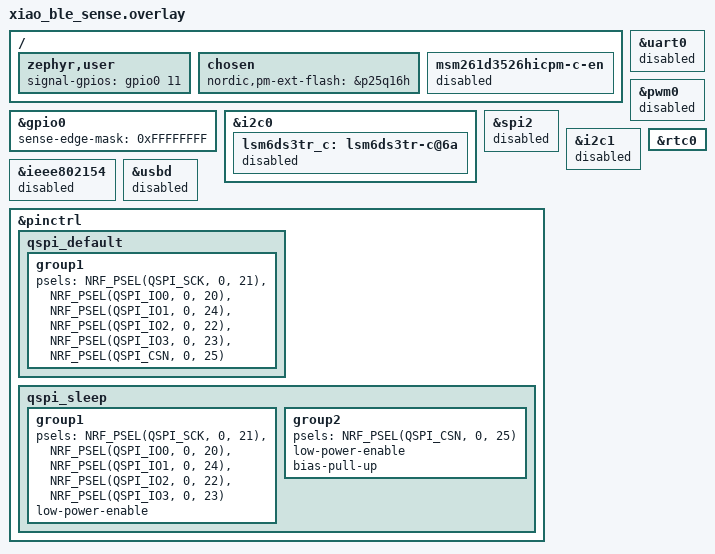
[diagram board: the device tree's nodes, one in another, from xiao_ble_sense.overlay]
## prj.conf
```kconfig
CONFIG_ASSERT=y
#memory
CONFIG_FLASH=y
CONFIG_FLASH_PAGE_LAYOUT=y
CONFIG_FLASH_MAP=y
CONFIG_NVS=y
CONFIG_NORDIC_QSPI_NOR=y
CONFIG_NORDIC_QSPI_NOR_FLASH_LAYOUT_PAGE_SIZE=4096
CONFIG_HEAP_MEM_POOL_SIZE=2048
CONFIG_NANOPB=y

#battery
CONFIG_ADC=y
CONFIG_ADC_NRFX_SAADC=y

CONFIG_I2C=y
CONFIG_SPI=n
CONFIG_CLOCK_CONTROL_NRF_K32SRC_XTAL=y
CONFIG_POSIX_CLOCK=y
CONFIG_BOARD_ENABLE_DCDC=y

#bluetooth
CONFIG_BT=y
CONFIG_SETTINGS=y
CONFIG_BT_SMP=y
CONFIG_BT_SIGNING=y
CONFIG_BT_PERIPHERAL=y
CONFIG_BT_ATT_PREPARE_COUNT=5
CONFIG_BT_BAS=y
#CONFIG_BT_DIS=y


CONFIG_BT_PRIVACY=y
CONFIG_BT_DEVICE_NAME="UU_tracker"
CONFIG_BT_DEVICE_APPEARANCE=541
CONFIG_BT_DEVICE_NAME_DYNAMIC=n
#CONFIG_BT_DEVICE_NAME_MAX=65
CONFIG_BT_SETTINGS=y
CONFIG_BT_USER_DATA_LEN_UPDATE=y


CONFIG_BT_BUF_ACL_RX_SIZE=83
CONFIG_BT_L2CAP_TX_MTU=83
CONFIG_BT_L2CAP_DYNAMIC_CHANNEL=y
CONFIG_BT_BUF_ACL_TX_COUNT=10
CONFIG_BT_BUF_ACL_TX_SIZE=83


CONFIG_BT_CTLR_DATA_LENGTH_MAX=83
CONFIG_BT_CTLR_PHY_2M=n
CONFIG_BT_CTLR_PHY_CODED=y

CONFIG_GPIO=y

#power savings
CONFIG_PM_DEVICE=y
CONFIG_USB_DEVICE_STACK=n
CONFIG_POWEROFF=y

CONFIG_LOG=n

#no-uf2
CONFIG_BUILD_OUTPUT_UF2=n
CONFIG_USE_DT_CODE_PARTITION=n
```

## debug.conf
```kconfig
#debug section
#xia debug
CONFIG_BUILD_OUTPUT_UF2=n
CONFIG_USE_DT_CODE_PARTITION=n

CONFIG_CORTEX_M_DEBUG_MONITOR_HOOK=y
CONFIG_SEGGER_DEBUGMON=y
CONFIG_DEBUG_OPTIMIZATIONS=y
CONFIG_DEBUG_THREAD_INFO=y
CONFIG_LOG=y 
CONFIG_BT_DEVICE_NAME="UU_tracker_DEBUG"

CONFIG_RTT_CONSOLE=y
CONFIG_USE_SEGGER_RTT=y

CONFIG_CBPRINTF_FP_SUPPORT=y
```

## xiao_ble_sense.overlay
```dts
/ {
    zephyr,user {
        signal-gpios = <&gpio0 11 GPIO_ACTIVE_HIGH>;
        
    };

    chosen {
        nordic,pm-ext-flash = &p25q16h;
    };

	msm261d3526hicpm-c-en {
		status = "disabled";
	};
};

&gpio0 {
    sense-edge-mask = <0xFFFFFFFF>; //<0x400>;
};


&i2c0 {	
    lsm6ds3tr_c: lsm6ds3tr-c@6a {
        status = "disabled";
    };
};

&uart0 {
    status = "disabled";
};

&pwm0 {
    status = "disabled"; 
};

&spi2 {
    status = "disabled";
};

&i2c1 {
    status = "disabled";
};

&ieee802154 {
    status = "disabled";
};

&rtc0 {
	status = "okay";
};

&usbd {
    status = "disabled";
};

&pinctrl {
    qspi_default: qspi_default {
		group1 {
			psels = <NRF_PSEL(QSPI_SCK, 0, 21)>,
				<NRF_PSEL(QSPI_IO0, 0, 20)>,
				<NRF_PSEL(QSPI_IO1, 0, 24)>,
				<NRF_PSEL(QSPI_IO2, 0, 22)>,
				<NRF_PSEL(QSPI_IO3, 0, 23)>,
				<NRF_PSEL(QSPI_CSN, 0, 25)>;
		};
	};

	qspi_sleep: qspi_sleep {
		group1 {
			psels = <NRF_PSEL(QSPI_SCK, 0, 21)>,
				<NRF_PSEL(QSPI_IO0, 0, 20)>,
				<NRF_PSEL(QSPI_IO1, 0, 24)>,
				<NRF_PSEL(QSPI_IO2, 0, 22)>,
				<NRF_PSEL(QSPI_IO3, 0, 23)>;
			low-power-enable;
		};
        group2 {
			psels = <NRF_PSEL(QSPI_CSN, 0, 25)>;
			low-power-enable;
			bias-pull-up;
		};
	};
};
```

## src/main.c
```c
#include <zephyr/kernel.h>
#include <zephyr/device.h>

#include <zephyr/devicetree.h>
#include <zephyr/drivers/gpio.h>

#include <stdio.h>
#include <zephyr/sys/util.h>
#include "storage_nvs.h"
#include "lsm6dsl_load.h"
#include "ble_load.h"
#include "battery.h"
#include <zephyr/logging/log.h>
#include <zephyr/sys/poweroff.h>

K_HEAP_DEFINE(BUFFER,512);

LOG_MODULE_REGISTER(MAIN, CONFIG_LOG_DEFAULT_LEVEL);

int main(void)
{		
	k_sleep(K_FOREVER);							
}
```

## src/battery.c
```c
/*
 * Copyright 2024 Marcus Alexander Tjomsaas
 *
 * Licensed under the Apache License, Version 2.0 (the "License");
 * you may not use this file except in compliance with the License.
 * You may obtain a copy of the License at
 *
 *     http://www.apache.org/licenses/LICENSE-2.0
 *
 * Unless required by applicable law or agreed to in writing, software
 * distributed under the License is distributed on an "AS IS" BASIS,
 * WITHOUT WARRANTIES OR CONDITIONS OF ANY KIND, either express or implied.
 * See the License for the specific language governing permissions and
 * limitations under the License.
 */

#include "battery.h"
#include <zephyr/bluetooth/services/bas.h>
#include <zephyr/kernel.h>
#include <zephyr/device.h>
#include <zephyr/devicetree.h>
#include <zephyr/drivers/gpio.h>
#include <zephyr/drivers/adc.h>
#include <zephyr/logging/log.h>

LOG_MODULE_REGISTER(battery, LOG_LEVEL_INF);

static void update_ble_handler(struct k_work *work);

K_WORK_DELAYABLE_DEFINE(ble_send_work, update_ble_handler);


static int16_t sample_buffer[ADC_TOTAL_SAMPLES];

static struct adc_sequence_options options = {
    .extra_samplings = ADC_TOTAL_SAMPLES - 1,
    .interval_us = ADC_SAMPLE_INTERVAL_US,
};

static struct adc_sequence sequence = {
    .options = &options,
    .channels = BIT(ADC_CHANNEL),
    .buffer = sample_buffer,
    .buffer_size = sizeof(sample_buffer),
    .resolution = ADC_RESOLUTION,
};

static struct adc_channel_cfg channel_7_cfg = {
    .gain = ADC_GAIN,
    .reference = ADC_REFERENCE,
    .acquisition_time = ADC_ACQ_TIME_DEFAULT,
    .channel_id = ADC_CHANNEL,
#ifdef CONFIG_ADC_NRFX_SAADC
    .input_positive = ADC_PORT
#endif
};

// MCU peripherals for reading battery voltage
static const struct device *gpio_battery_dev = DEVICE_DT_GET(DT_NODELABEL(gpio0));
static const struct device *adc_battery_dev = DEVICE_DT_GET(DT_NODELABEL(adc));

// Charging interrupt

static K_MUTEX_DEFINE(battery_mut);

// Assuming LiPo battery.
// For better accuracy, use your battery's datasheet.
static BatteryState battery_states[BATTERY_STATES_COUNT] = {
    {4200, 100},
    {4160, 99},
    {4090, 91},
    {4030, 78},
    {3890, 63},
    {3830, 53},
    {3680, 36},
    {3660, 35},
    {3480, 14},
    {3420, 11},
    {3150, 1}, // 3240
    {0000, 0}  // Below safe level
};

int battery_get_millivolt(uint16_t *battery_millivolt)
{

    int ret = 0;

    // Voltage divider circuit (Should tune R1 in software if possible)
    const uint16_t R1 = 1037; // Originally 1M ohm, calibrated after measuring actual voltage values. Can happen due to resistor tolerances, temperature ect..
    const uint16_t R2 = 510;  // 510K ohm
    
    int adc_mv = 0;
    
    ret |= k_mutex_lock(&battery_mut, K_FOREVER);
    ret |= gpio_pin_set(gpio_battery_dev, GPIO_BATTERY_READ_ENABLE, 1);
    ret |= adc_read(adc_battery_dev, &sequence);
    uint16_t adc_vref = adc_ref_internal(adc_battery_dev);

    // Get average sample value.
    for (uint8_t sample = 0; sample < ADC_TOTAL_SAMPLES; sample++)
    {
        adc_mv += sample_buffer[sample]; // ADC value, not millivolt yet.
    }
    adc_mv /= ADC_TOTAL_SAMPLES;

    // Convert ADC value to millivolts
    ret |= adc_raw_to_millivolts(adc_vref, ADC_GAIN, ADC_RESOLUTION, &adc_mv);

    // Calculate battery voltage.
    *battery_millivolt = adc_mv * ((R1 + R2) / R2);

    ret |= gpio_pin_set(gpio_battery_dev, GPIO_BATTERY_READ_ENABLE, 0);

    k_mutex_unlock(&battery_mut);

    LOG_DBG("%d mV", *battery_millivolt);
    return ret;
}

int battery_get_percentage(uint8_t *battery_percentage, uint16_t battery_millivolt)
{

    // Ensure voltage is within bounds
    if (battery_millivolt > battery_states[0].voltage)
        *battery_percentage = 100;
    if (battery_millivolt < battery_states[BATTERY_STATES_COUNT - 1].voltage)
        *battery_percentage = 0;

    for (uint16_t i = 0; i < BATTERY_STATES_COUNT - 1; i++)
    {
        // Find the two points battery_millivolt is between
        if (battery_states[i].voltage >= battery_millivolt && battery_millivolt >= battery_states[i + 1].voltage)
        {
            // Linear interpolation
            *battery_percentage = battery_states[i].percentage +
                                  ((float)(battery_millivolt - battery_states[i].voltage) *
                                   ((float)(battery_states[i + 1].percentage - battery_states[i].percentage) /
                                    (float)(battery_states[i + 1].voltage - battery_states[i].voltage)));

            LOG_DBG("%d %%", *battery_percentage);
            return 0;
        }
    }
    return -ESPIPE;
}


static void update_ble_handler(struct k_work *work) {
    
    uint8_t percentage = 0;
    uint16_t millivolt = 0;
    battery_get_millivolt(&millivolt);

    battery_get_percentage(&percentage, millivolt);
    bt_bas_set_battery_level(percentage);
    LOG_INF("update_ble mV %d, percentage %d", millivolt, percentage);
    k_work_schedule(&ble_send_work, K_MINUTES(BAS_UPDATE_FREQUENCY));
}

int battery_init()
{
    int ret = 0;

    ret |= adc_channel_setup(adc_battery_dev, &channel_7_cfg);        
    ret |= gpio_pin_configure(gpio_battery_dev, GPIO_BATTERY_READ_ENABLE, GPIO_OUTPUT | GPIO_ACTIVE_LOW);
    ret |= gpio_pin_configure(gpio_battery_dev, GPIO_BATTERY_CHARGE_SPEED, GPIO_OUTPUT | GPIO_ACTIVE_LOW);
    ret |= gpio_pin_set(gpio_battery_dev, GPIO_BATTERY_CHARGE_SPEED, 1); // FAST charge 100mA
    
    LOG_INF("Initialized");
    
    k_work_schedule(&ble_send_work, K_MINUTES(BAS_UPDATE_FREQUENCY));

    return ret;
}

SYS_INIT(battery_init, APPLICATION, CONFIG_APPLICATION_INIT_PRIORITY);
```

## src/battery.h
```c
/*
 * Copyright 2024 Marcus Alexander Tjomsaas
 *
 * Licensed under the Apache License, Version 2.0 (the "License");
 * you may not use this file except in compliance with the License.
 * You may obtain a copy of the License at
 *
 *     http://www.apache.org/licenses/LICENSE-2.0
 *
 * Unless required by applicable law or agreed to in writing, software
 * distributed under the License is distributed on an "AS IS" BASIS,
 * WITHOUT WARRANTIES OR CONDITIONS OF ANY KIND, either express or implied.
 * See the License for the specific language governing permissions and
 * limitations under the License.
 */

#include <stdint.h>
#include <stdbool.h>

#ifndef __BATTERY_H__
#define __BATTERY_H__

#define BAS_UPDATE_FREQUENCY 2
#define GPIO_BATTERY_CHARGE_SPEED 13
#define GPIO_BATTERY_CHARGING_ENABLE 17
#define GPIO_BATTERY_READ_ENABLE 14

// Change this to a higher number for better averages
// Note that increasing this holds up the thread / ADC for longer.
#define ADC_TOTAL_SAMPLES 10

//--------------------------------------------------------------
// ADC setup

#define ADC_RESOLUTION 12
#define ADC_CHANNEL 7
#define ADC_PORT SAADC_CH_PSELP_PSELP_AnalogInput7 // AIN7
#define ADC_REFERENCE ADC_REF_INTERNAL             // 0.6V
#define ADC_GAIN ADC_GAIN_1_6                      // ADC REFERENCE * 6 = 3.6V
#define ADC_SAMPLE_INTERVAL_US 500                 // Time between each sample
#define BATTERY_STATES_COUNT 12


typedef struct
{
    uint16_t voltage;
    uint8_t percentage;
} BatteryState;


/**
 * @brief Calculates the battery voltage using the ADC.
 *
 * @param[in] battery_millivolt Pointer to where battery voltage is stored.
 *
 * @retval 0 if successful. Negative errno number on error.
 */
int battery_get_millivolt(uint16_t *battery_millivolt);

/**
 * @brief Calculates the battery percentage using the battery voltage.
 *
 * @param[in] battery_percentage  Pointer to where battery percentage is stored.
 *
 * @param[in] battery_millivolt Voltage used to calculate the percentage of how much energy is left in a 3.7V LiPo battery.
 *
 * @retval 0 if successful. Negative errno number on error.
 */
int battery_get_percentage(uint8_t *battery_percentage, uint16_t battery_millivolt);


#endif
```

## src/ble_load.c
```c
#include <zephyr/types.h>
#include <stddef.h>
#include <string.h>
#include <errno.h>

#include <zephyr/sys/byteorder.h>
#include <zephyr/kernel.h>

#include <zephyr/settings/settings.h>

#include <zephyr/bluetooth/bluetooth.h>
#include <zephyr/bluetooth/hci.h>
#include <zephyr/bluetooth/conn.h>
#include <zephyr/bluetooth/uuid.h>
#include <zephyr/bluetooth/gatt.h>

#include <zephyr/logging/log.h>
#include <pb_encode.h>
#include <pb_decode.h>
#include "motion.pb.h"
#include "storage_nvs.h"


#define protobuf_chunk_size 64 //*13 = 247, actual 246 byte protobuf total/max mTU= 20byte
#define protobuf_buffer_size ROUND_UP(HourlyResult_size, protobuf_chunk_size)
//#define ble_chunks_to_send ROUND_UP(HourlyResult_size/protobuf_chunk_size, 1) //more than enough

LOG_MODULE_REGISTER(bluetooth_m, CONFIG_LOG_DEFAULT_LEVEL);

void ble_notify_motiondata_proc(struct k_work *ptrWorker);
void ble_send_passcode(struct k_work *work);

K_WORK_DEFINE(ble_passcode_worker, ble_send_passcode);
K_WORK_DEFINE(work_get_acc_data, ble_notify_motiondata_proc);

//custom service
static struct bt_uuid_128 motiondata_prop = BT_UUID_INIT_128(
	BT_UUID_128_ENCODE(0xa6c47c93, 0x8a09, 0x4ca5, 0x976e, 0xde7b871f11f0));

//ble key
static struct bt_uuid_128 ble_pw_prop = BT_UUID_INIT_128(
	BT_UUID_128_ENCODE(0xd97b1503, 0xa25c, 0x4295, 0xbd21, 0xf96823d91552));

//unique device
static struct bt_uuid_128 ble_device_identifier_prop = BT_UUID_INIT_128(
	BT_UUID_128_ENCODE(0x56a332cc, 0x0379, 0x497e, 0xbd2d, 0xe778c69badd6));

//current memory position
static struct bt_uuid_128 ble_memory_position_prop = BT_UUID_INIT_128(
	BT_UUID_128_ENCODE(0x84b45135, 0x170b, 0x4d03, 0x92b6, 0x386d7bff160d));

//accelometer data server (protobuf)
static struct bt_uuid_128 ble_accelometer_data_prop = BT_UUID_INIT_128(
	BT_UUID_128_ENCODE(0x6f2648ed, 0xe73f, 0x4b9f, 0xa809, 0xb1686d18676c));

//accelometer requist data
static struct bt_uuid_128 ble_accelometer_requist_id_prop = BT_UUID_INIT_128(
	BT_UUID_128_ENCODE(0x4e10fd71, 0x6cc1, 0x4fa7, 0xaa91, 0x82021582ca54));



static uint8_t ble_accelometer_data_buff[protobuf_chunk_size]; //size of packed protobuf
static uint8_t ble_requist_id_buff[2]; //uint16 flash location

//write flash ID to respond to
static ssize_t write_acc_data_position(struct bt_conn *conn, const struct bt_gatt_attr *attr,
 			 const void *buf, uint16_t len, uint16_t offset,
 			 uint8_t flags) {

 	uint8_t *value = attr->user_data;

	if (offset + len > sizeof(ble_requist_id_buff)) {
		return BT_GATT_ERR(BT_ATT_ERR_INVALID_OFFSET);
	}
	memcpy(value + offset, buf, len);	
	
	k_work_submit(&work_get_acc_data);
	
 	return len;
}
//read flash ID that has been responded to
static ssize_t read_acc_data_position(struct bt_conn *conn, const struct bt_gatt_attr *attr,
			void *buf, uint16_t len, uint16_t offset)
{
	const uint8_t *value = attr->user_data;	

	return bt_gatt_attr_read(conn, attr, buf, len, offset, value, sizeof(ble_requist_id_buff));
}

//read last chunk of protobuffed data 
static ssize_t read_acc_data(struct bt_conn *conn, const struct bt_gatt_attr *attr,
			void *buf, uint16_t len, uint16_t offset)
{	
	
	const uint8_t *value = attr->user_data;	

	return bt_gatt_attr_read(conn, attr, buf, len, offset, value, sizeof(ble_accelometer_data_buff));
}

//protobuf encode sensor data 
//todo: might want to use double?
static int encode_data(struct fifo_pack *stored_data, uint8_t *protobuf_packed, size_t *packed_size) {
	bool status;

	HourlyResult message = HourlyResult_init_zero;	
	/* Create a stream that will write to our buffer. */
	pb_ostream_t stream = pb_ostream_from_buffer(protobuf_packed, HourlyResult_size);
	
	message.UnixTime = stored_data->seconds_passed;

	BUILD_ASSERT(ARRAY_SIZE(message.AvgMinuteList) == FLASH_BUFFER_SIZE_NVS, "Error buffer not equal to array size");
	for(int i = 0; i<FLASH_BUFFER_SIZE_NVS; i++) {
		message.AvgMinuteList[i] = stored_data->vector_n[i];
	}	

	status = pb_encode(&stream, &HourlyResult_msg, &message);
	*packed_size = stream.bytes_written;

	LOG_INF("Encoded, actual protobuf message size was %d", stream.bytes_written); //PRIu64

	if (!status) {
		LOG_ERR("Encoding failed: %s\n", PB_GET_ERROR(&stream));
	}

	return status;
}


static uint8_t current_memoryPosition_buff[2];
static ssize_t read_memory_position(struct bt_conn *conn, const struct bt_gatt_attr *attr,
			void *buf, uint16_t len, uint16_t offset)
{
	uint16_t mem_pos = 0;
	get_current_storage_id(&mem_pos);
	memcpy(current_memoryPosition_buff, &mem_pos, sizeof(uint16_t));

	const uint8_t *value = attr->user_data;	

	return bt_gatt_attr_read(conn, attr, buf, len, offset, value, sizeof(current_memoryPosition_buff));
}

static ssize_t write_memory_position(struct bt_conn *conn, const struct bt_gatt_attr *attr,
 			 const void *buf, uint16_t len, uint16_t offset,
 			 uint8_t flags) {

 	uint8_t *value = attr->user_data;

	if (offset + len > sizeof(current_memoryPosition_buff)) {
		return BT_GATT_ERR(BT_ATT_ERR_INVALID_OFFSET);
	}
	memcpy(value + offset, buf, len);

	uint16_t memory_position = 0;
	memcpy(&memory_position, current_memoryPosition_buff, sizeof(uint16_t));
	set_current_storage_id(&memory_position);
	//memcpy(&memory_position, value, sizeof(uint16_t));	
	
 	return len;
}


static uint8_t ble_passcode_buff[4];
static ssize_t read_passcode(struct bt_conn *conn, const struct bt_gatt_attr *attr,
			void *buf, uint16_t len, uint16_t offset)
{
	const uint8_t *value = attr->user_data;	

	return bt_gatt_attr_read(conn, attr, buf, len, offset, value, sizeof(ble_passcode_buff));
}

static uint8_t uniqueIdentifier_value[sizeof(uint16_t)];

static ssize_t read_identifier(struct bt_conn *conn, const struct bt_gatt_attr *attr,
			void *buf, uint16_t len, uint16_t offset) {

	uint16_t uniqueId = 0;
	read_uniqueidentifier(&uniqueId);
	memcpy(uniqueIdentifier_value, &uniqueId, sizeof(uint16_t));

	const uint8_t *value = attr->user_data;	

	return bt_gatt_attr_read(conn, attr, buf, len, offset, value, sizeof(uniqueIdentifier_value));
}

static ssize_t write_identifier(struct bt_conn *conn, const struct bt_gatt_attr *attr,
 			 const void *buf, uint16_t len, uint16_t offset,
 			 uint8_t flags) {

 	uint8_t *value = attr->user_data;

	if (offset + len > sizeof(uniqueIdentifier_value)) {
		return BT_GATT_ERR(BT_ATT_ERR_INVALID_OFFSET);
	}
	memcpy(value + offset, buf, len);

	uint16_t uniqueId = 0;
	memcpy(&uniqueId, value, sizeof(uint16_t));
	write_uniqueIdentifier(&uniqueId);
	
 	return len;
}

static uint8_t notify_ble_passcode_on = 0;
static uint8_t notify_ble_motiondata_on = 0;

static void ble_readmotion_data_notify_changed(const struct bt_gatt_attr *attr, uint16_t value) {
	notify_ble_motiondata_on = (value == BT_GATT_CCC_NOTIFY) ? 1 : 0;
}

static void ble_passcode_notify_changed(const struct bt_gatt_attr *attr, uint16_t value) {
	notify_ble_passcode_on = (value == BT_GATT_CCC_NOTIFY) ? 1 : 0;
}

/* Motion readout primary Service Declaration */
BT_GATT_SERVICE_DEFINE(motion_svc,
	BT_GATT_PRIMARY_SERVICE(&motiondata_prop),
	BT_GATT_CHARACTERISTIC(&ble_pw_prop.uuid,
			       BT_GATT_CHRC_READ | BT_GATT_CHRC_NOTIFY,
			       BT_GATT_PERM_READ,
			       read_passcode, NULL, ble_passcode_buff),	
	BT_GATT_CCC(ble_passcode_notify_changed,   BT_GATT_PERM_READ | BT_GATT_PERM_WRITE),
	
	BT_GATT_CHARACTERISTIC(&ble_device_identifier_prop.uuid,
			       BT_GATT_CHRC_READ | BT_GATT_CHRC_WRITE,
			       BT_GATT_PERM_READ | BT_GATT_PERM_WRITE,
			       read_identifier, write_identifier, uniqueIdentifier_value),

	BT_GATT_CHARACTERISTIC(&ble_memory_position_prop.uuid, 
	 		       BT_GATT_CHRC_READ | BT_GATT_CHRC_WRITE,
	 		       BT_GATT_PERM_READ | BT_GATT_PERM_WRITE,	 		       
	 		       read_memory_position, write_memory_position, current_memoryPosition_buff),

	BT_GATT_CHARACTERISTIC(&ble_accelometer_data_prop.uuid, 
	 		       BT_GATT_CHRC_READ | BT_GATT_CHRC_NOTIFY,
	 		       BT_GATT_PERM_READ,
	 		       read_acc_data, NULL, ble_accelometer_data_buff),
	BT_GATT_CCC(ble_readmotion_data_notify_changed, BT_GATT_PERM_READ | BT_GATT_PERM_WRITE),
	
	BT_GATT_CHARACTERISTIC(&ble_accelometer_requist_id_prop.uuid, 
	 		       BT_GATT_CHRC_READ | BT_GATT_CHRC_WRITE,
	 		       BT_GATT_PERM_READ | BT_GATT_PERM_WRITE,
	 		       read_acc_data_position, write_acc_data_position, ble_requist_id_buff),

);

void ble_send_passcode(struct k_work *work) {				
	
	if(notify_ble_passcode_on)
		bt_gatt_notify(NULL, &motion_svc.attrs[1], ble_passcode_buff, sizeof(ble_passcode_buff));	
}

void print_data(uint8_t *data, uint32_t len) {
	char string[255] = {0};
    
    
    LOG_INF("%s\n", string);
}

K_SEM_DEFINE(sem_notify, 0, 1);

void notify_complete_cb(struct bt_conn *conn, void *user_data)
{
	int err = 0;
    if (err != 0) {
        LOG_ERR("Notification failed with error %d", err);
        return;
    }
	k_sem_give(&sem_notify);
}


/// @brief Notify BLE with all chunks of data 
/// @param ptrWorker 
void ble_notify_motiondata_proc(struct k_work *ptrWorker) {					

	if(!notify_ble_motiondata_on) return;
	struct fifo_pack packet;
	uint16_t id_to_retreive;
	memcpy(&id_to_retreive, ble_requist_id_buff, sizeof(uint16_t));
	LOG_INF("NOTIFY data, reteive id %d", id_to_retreive);				
	load_tracked(id_to_retreive, &packet);
	
	uint8_t encoded_data_cache[protobuf_buffer_size] = {0};
	size_t packed_size = 0;
	encode_data(&packet, encoded_data_cache+2, &packed_size); //shift data 2 bytes
	memcpy(encoded_data_cache, &packed_size, sizeof(uint16_t)); //first 2 bytes for size

	struct bt_gatt_attr *notify_attr = bt_gatt_find_by_uuid(motion_svc.attrs, motion_svc.attr_count, &ble_accelometer_data_prop.uuid);
	
    struct bt_gatt_notify_params params = {
        .attr = notify_attr,
        .data = ble_accelometer_data_buff,
        .len  = sizeof(ble_accelometer_data_buff),
        .func = notify_complete_cb, 
    };

	for(size_t offset = 0; offset < packed_size; offset+=protobuf_chunk_size) {
		memcpy(ble_accelometer_data_buff, encoded_data_cache + offset, protobuf_chunk_size);	
				
		LOG_INF("sending offset %d", offset);
		
		int ret = bt_gatt_notify_cb(NULL, &params);
		int semret = k_sem_take(&sem_notify, K_MSEC(200));
		if(ret<0) {
			LOG_ERR("error notify data %d", ret);	
		}			
		if(semret == -EAGAIN) {			
			LOG_ERR("semaphone timed out");
			return;
		}
	}	
}

const struct bt_data ad[] = {
		BT_DATA_BYTES(BT_DATA_FLAGS, (BT_LE_AD_GENERAL | BT_LE_AD_NO_BREDR)),
		BT_DATA_BYTES(BT_DATA_UUID16_ALL, BT_UUID_16_ENCODE(BT_UUID_BAS_VAL), BT_UUID_16_ENCODE(BT_UUID_CTS_VAL)),	};
		//BT_DATA_BYTES(BT_DATA_UUID128_ALL, motiondata_prop),
// 			BT_DATA(BT_DATA_MANUFACTURER_DATA, uniqueId, sizeof(ui))
// 	};
// }

void mtu_updated(struct bt_conn *conn, uint16_t tx, uint16_t rx)
{
	LOG_INF("Updated MTU: TX: %d RX: %d bytes\n", tx, rx);
}

static struct bt_gatt_cb gatt_callbacks = {
	.att_mtu_updated = mtu_updated
};

static void connected(struct bt_conn *conn, uint8_t err)
{
	if (err) {
		LOG_INF("Connection failed (err 0x%02x)\n", err);
	} else {
		LOG_INF("Connected\n");
	}
}

static void disconnected(struct bt_conn *conn, uint8_t reason)
{
	LOG_INF("Disconnected (reason 0x%02x)\n", reason);
}

static void le_data_length_updated(struct bt_conn *conn, struct bt_conn_le_data_len_info *info) {
	LOG_INF("LE data len updated: TX (len: %d time: %d)"
	       " RX (len: %d time: %d)\n", info->tx_max_len,
	       info->tx_max_time, info->rx_max_len, info->rx_max_time);
}

BT_CONN_CB_DEFINE(conn_callbacks) = {
	.connected = connected,
	.disconnected = disconnected,
	.le_data_len_updated = le_data_length_updated,
};



#define BT_CONN_CUSTOM BT_LE_ADV_PARAM(BT_LE_ADV_OPT_CONNECTABLE | \
					    BT_LE_ADV_OPT_USE_NAME, \
					    2048+512+64, 4098, NULL) //*1.25ms

static void bt_ready(void)
{
	int err;

	LOG_INF("Bluetooth initialized\n");	

	if (IS_ENABLED(CONFIG_SETTINGS)) {
		settings_load();
	}

	err = bt_le_adv_start(BT_CONN_CUSTOM, ad, ARRAY_SIZE(ad), NULL, 0);
	if (err) {
		LOG_ERR("Advertising failed to start (err %d)\n", err);
		return;
	}

	LOG_INF("Advertising successfully started\n");
}
/*
static void auth_passkey_display(struct bt_conn *conn, unsigned int passkey)
{
	char addr[BT_ADDR_LE_STR_LEN];
	bt_addr_le_to_str(bt_conn_get_dst(conn), addr, sizeof(addr));
	LOG_INF("Passkey for %s: %06u\n", addr, passkey);
	memcpy(ble_passcode_buff, (uint8_t*)&passkey, (sizeof(ble_passcode_buff)));	
	k_work_submit(&ble_passcode_worker);
	bt_conn_auth_passkey_confirm(conn);
}
*/
static void auth_cancel(struct bt_conn *conn)
{
	char addr[BT_ADDR_LE_STR_LEN];

	bt_addr_le_to_str(bt_conn_get_dst(conn), addr, sizeof(addr));

	LOG_INF("Pairing cancelled: %s\n", addr);
}

static struct bt_conn_auth_cb auth_cb_display = {
	.passkey_display = NULL,// auth_passkey_display,
	.passkey_entry = NULL,
	.cancel = auth_cancel,
	.passkey_confirm = NULL,	
};

int ble_load()
{		
	int err;

	err = bt_enable(NULL);
	if (err) {
		LOG_INF("Bluetooth init failed (err %d)\n", err);
		return 0;
	}

	bt_ready();

	bt_gatt_cb_register(&gatt_callbacks);
	bt_conn_auth_cb_register(&auth_cb_display);

	//clean up bonds
	bt_unpair(BT_ID_DEFAULT, BT_ADDR_LE_ANY);
	
	return err;
}

SYS_INIT(ble_load, APPLICATION, CONFIG_APPLICATION_INIT_PRIORITY);
```

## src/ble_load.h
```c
#ifndef BLE_LOAD_H
#define BLE_LOAD_H



#endif
```

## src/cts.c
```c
/** @file
 *  @brief CTS Service sample
 */

/*
 * Copyright (c) 2016 Intel Corporation
 *
 * SPDX-License-Identifier: Apache-2.0
 */

#include <zephyr/types.h>
#include <stddef.h>
#include <errno.h>
#include <zephyr/sys/byteorder.h>
#include <zephyr/kernel.h>

#include <zephyr/bluetooth/bluetooth.h>
#include <zephyr/bluetooth/hci.h>
#include <zephyr/bluetooth/conn.h>
#include <zephyr/bluetooth/uuid.h>
#include <zephyr/bluetooth/gatt.h>

#include <zephyr/posix/time.h>
#include <zephyr/sys/timeutil.h>
#include <zephyr/logging/log.h>
#include "cts.h"

//current time
static uint8_t ct[sizeof(time_t)];

LOG_MODULE_REGISTER(TIME_MODULE, CONFIG_LOG_DEFAULT_LEVEL);

void ble_update_time(struct k_work *work);

void timerElapsed(struct k_timer *timer_id);
K_WORK_DEFINE(notifyCTS, ble_update_time);

K_TIMER_DEFINE(update_time_timer, timerElapsed, NULL);

void timerElapsed(struct k_timer *timer_id) {
	k_work_submit(&notifyCTS);
}

void update_time_ble_buffer() {
	struct timespec ts = {
        .tv_sec = 0,
        .tv_nsec = 0,
    };

	clock_gettime(CLOCK_REALTIME, &ts);
	LOG_INF("update time, current: %" PRId64 ", size %d" , ts.tv_sec, sizeof(time_t));
	memcpy(&ct, &ts.tv_sec, sizeof(time_t));
}

static void ct_ccc_cfg_changed(const struct bt_gatt_attr *attr, uint16_t value)
{

	if(value) {
		k_timer_start(&update_time_timer, K_SECONDS(1), K_SECONDS(1));

	} else {
		k_timer_stop(&update_time_timer);
	}
}

static ssize_t read_ct(struct bt_conn *conn, const struct bt_gatt_attr *attr,
		       void *buf, uint16_t len, uint16_t offset)
{
	update_time_ble_buffer();
	const char *value = attr->user_data;	

	return bt_gatt_attr_read(conn, attr, buf, len, offset, value,
				 sizeof(ct));
}

int settime(time_t current_time) {
	int ret = 0;
	struct timespec ts = {0};
	ts.tv_sec = current_time;

    ret |= clock_settime(CLOCK_REALTIME, &ts);
	
	return ret;
}

static ssize_t write_ct(struct bt_conn *conn, const struct bt_gatt_attr *attr,
			const void *buf, uint16_t len, uint16_t offset,
			uint8_t flags)
{
	uint8_t *value = attr->user_data;

	if (offset + len > sizeof(ct)) {
		return BT_GATT_ERR(BT_ATT_ERR_INVALID_OFFSET);
	}

	memcpy(value + offset, buf, len);
		
	for(uint16_t i = 0; i<len; i++){
		LOG_INF("received %i", value[i]);
	}
	time_t timeconstruct = 0;
	memcpy(&timeconstruct, value, len);
	
	settime(timeconstruct);
	print_current_time();

	return len;
}

int print_current_time() {
	
    struct timespec ts = {0};      
	
	clock_gettime(CLOCK_REALTIME, &ts);
	struct tm *current_time = gmtime(&ts.tv_sec);

	LOG_INF("Current time: %04d-%02d-%02d %02d:%02d:%02d",
			current_time->tm_year + 1900, current_time->tm_mon + 1, current_time->tm_mday,
			current_time->tm_hour, current_time->tm_min, current_time->tm_sec);
	
	return 0;
}

/* Current Time Service Declaration */
BT_GATT_SERVICE_DEFINE(cts_cvs,
	BT_GATT_PRIMARY_SERVICE(BT_UUID_CTS),
	BT_GATT_CHARACTERISTIC(BT_UUID_CTS_CURRENT_TIME, BT_GATT_CHRC_READ |
			       BT_GATT_CHRC_NOTIFY | BT_GATT_CHRC_WRITE,
			       BT_GATT_PERM_READ | BT_GATT_PERM_WRITE,
			       read_ct, write_ct, ct),
	BT_GATT_CCC(ct_ccc_cfg_changed, BT_GATT_PERM_READ | BT_GATT_PERM_WRITE),
);

void ble_update_time(struct k_work *work)
{
    
	update_time_ble_buffer();
	// struct bt_gatt_attr *cts_not_attr;
	// cts_not_attr = bt_gatt_find_by_uuid(cts_cvs.attrs, cts_cvs.attr_count, BT_UUID_CTS_CURRENT_TIME);					
	
	bt_gatt_notify(NULL, &cts_cvs.attrs[1], ct, sizeof(ct));
	
}


//SYS_INIT(cts_init, APPLICATION, CONFIG_APPLICATION_INIT_PRIORITY);
```

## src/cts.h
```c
#ifndef CTS_LOAD_H
#define CTS_LOAD_H

int print_current_time();


#endif
```

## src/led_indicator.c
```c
#include <stdio.h>
#include <zephyr/kernel.h>
#include <zephyr/device.h>
#include <zephyr/drivers/gpio.h>


#define LED0_NODE DT_ALIAS(led0)
#define LED1_NODE DT_ALIAS(led1)
#define LED2_NODE DT_ALIAS(led2)
#define number_leds 3

static const struct gpio_dt_spec leds[] = {
    GPIO_DT_SPEC_GET(LED0_NODE, gpios),
    GPIO_DT_SPEC_GET(LED1_NODE, gpios),    
    GPIO_DT_SPEC_GET(LED2_NODE, gpios),    
};

static void switchof(struct k_work *work);

struct k_work_delayable dw_switchoffs [number_leds];

static int led_init() {
    int ret = 0;
    for(int x = 0; x< number_leds; x++) {
        ret |= gpio_pin_configure_dt(&leds[x], GPIO_OUTPUT_ACTIVE);
        ret |= gpio_pin_set_dt(&leds[x], 0);
        k_work_init_delayable(&dw_switchoffs[x], switchof);  
    }    
    
    return ret;
}

//K_WORK_DELAYABLE_DEFINE(dw_switchof, switchof);

static void switchof(struct k_work *work) {    
    struct k_work_delayable *dwork = k_work_delayable_from_work(work);
    int index = dwork - dw_switchoffs;    
    gpio_pin_set_dt(&leds[index], 0);    
}

void blink(uint8_t color) {    
    gpio_pin_set_dt(&leds[color], 1);
    k_work_schedule(&dw_switchoffs[color], K_MSEC(768));
}

SYS_INIT(led_init, APPLICATION, CONFIG_APPLICATION_INIT_PRIORITY);
```

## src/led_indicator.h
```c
#ifndef __led_indicator
#define __led_indicator



void blink(uint8_t color);

#endif
```

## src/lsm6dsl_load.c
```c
#include <zephyr/kernel.h>
#include <zephyr/device.h>
#include <zephyr/sys/util.h>
#include <zephyr/drivers/gpio.h>
#include <zephyr/drivers/i2c.h>
#include <zephyr/logging/log.h>
#include <math.h>
#include "storage_nvs.h"
#include "lsm6dsl_reg.h"
#include "lsm6dsl_load.h"
#include "led_indicator.h"

#include <zephyr/bluetooth/bluetooth.h>
#include <zephyr/bluetooth/hci.h>
#include <zephyr/bluetooth/conn.h>
#include <zephyr/bluetooth/uuid.h>
#include <zephyr/bluetooth/gatt.h>



BUILD_ASSERT(FIFO_BUFFER_LENGTH % fifo_pattern == 0, "FIFO_BUFFER_LENGTH should be devisible by fifo_pattern");

static const struct gpio_dt_spec signal = GPIO_DT_SPEC_GET(ZEPHYR_USER_NODE, signal_gpios);

LOG_MODULE_REGISTER(LSM6DSL_LOAD, CONFIG_LOG_DEFAULT_LEVEL);

static uint8_t whoamI, rst;
const struct device *i2c;
static struct gpio_callback lsm6dsl_interrupt;
static stmdev_ctx_t dev_ctx;

typedef union {
  int16_t i16bit[3];
  uint8_t u8bit[6];
} axis3bit16_t;

static axis3bit16_t data_raw_acceleration;

void lsm6dsl_isr(const struct device *dev, struct gpio_callback *cb, uint32_t pins);

static void lsm6dsl_data_handler(struct k_work *work);
K_WORK_DELAYABLE_DEFINE(lsm6dsl_proces, lsm6dsl_data_handler);


void attachinterrupt(void) {

	__ASSERT(device_is_ready(signal.port), "custom device not ready");
	if(gpio_pin_configure_dt(&signal, GPIO_INPUT)) {
    LOG_ERR("error configure signalgpio");
  }

	if(gpio_pin_interrupt_configure_dt(&signal, GPIO_INT_EDGE_TO_ACTIVE)) {  
    LOG_ERR("error configure interrupt signalgpio");
  };
	gpio_init_callback(&lsm6dsl_interrupt, lsm6dsl_isr, BIT(signal.pin));
	if(gpio_add_callback(signal.port, &lsm6dsl_interrupt)) {
    LOG_ERR("callback for interrupt not set");
 };
}

/* Private functions ---------------------------------------------------------*/

static int32_t platform_write(void *handle, uint8_t reg, const uint8_t *bufp,
                              uint16_t len);
static int32_t platform_read(void *handle, uint8_t reg, uint8_t *bufp,
                             uint16_t len);

static void platform_delay(uint32_t ms);
static void platform_init(void);

void lsm6dsl_isr(const struct device *dev, struct gpio_callback *cb, uint32_t pins) {  
  //gpio_pin_interrupt_configure_dt(&signal, GPIO_INT_DISABLE);
  LOG_INF("isr given");

  k_work_schedule(&lsm6dsl_proces, K_NO_WAIT); 
}

struct xlData {
    float x;
    float y;
    float z;
};  

int lsm6dsl_set_interrupts(bool withDoubletap) {
  int ret = 0;
  lsm6dsl_int1_route_t intset1 = { .int1_fth = 1, /*.int1_tilt = 1, */ .int1_sign_mot = 1, .int1_double_tap = withDoubletap};
  ret |= lsm6dsl_pin_int1_route_set(&dev_ctx, intset1); 
  return ret;
}

static bool sigMotionDetected = false;

/// @brief Enables significant motion detection
/// @return 0 if succeed
int lsm6dsl_config_doubletap(bool setEnabled) {
  int ret = 0;

  lsm6dsl_xl_data_rate_set(&dev_ctx, setEnabled ? LSM6DSL_XL_ODR_416Hz : LSM6DSL_XL_ODR_52Hz); 
  lsm6dsl_tap_cfg_t tap_cfg = {.tap_x_en = setEnabled, .tap_y_en = setEnabled, .tap_z_en = setEnabled, .interrupts_enable =setEnabled, .inact_en = 0, .slope_fds = 0};
  lsm6dsl_tap_ths_6d_t tab_ths = {.tap_ths =12, .d4d_en =1};
  lsm6dsl_int_dur2_t tap_dur = {.dur = 7, .quiet =3, .shock = 3};
  lsm6dsl_wake_up_ths_t tap_ths = {.single_double_tap = 1};
  //lsm6dsl_xl_hp_path_internal_set(&dev_ctx, &tap_cfg);
  ret |= lsm6dsl_write_reg(&dev_ctx, LSM6DSL_TAP_CFG, (uint8_t *)&tap_cfg, 1);
  ret |= lsm6dsl_write_reg(&dev_ctx, LSM6DSL_TAP_THS_6D, (uint8_t*)&tab_ths, 1);
  ret |= lsm6dsl_write_reg(&dev_ctx, LSM6DSL_INT_DUR2, (uint8_t *)&tap_dur, 1);
  ret |= lsm6dsl_write_reg(&dev_ctx, LSM6DSL_WAKE_UP_THS, (uint8_t *)&tap_ths, 1);

  lsm6dsl_set_interrupts(setEnabled);
  
  return ret;
}



int lsm6dsl_init(/*struct storage_module *storage */)
{  
  
  int ret = 0;
  attachinterrupt();
  /* Initialize mems driver interface */  
  dev_ctx.write_reg = platform_write;
  dev_ctx.read_reg = platform_read;
  dev_ctx.mdelay = platform_delay;
  
  /* Init test platform */
  platform_init();
  /* Wait sensor boot time */
  platform_delay(BOOT_TIME);
  /* Check device ID */
  whoamI = 0;
  ret |= lsm6dsl_device_id_get(&dev_ctx, &whoamI);
  

  if ( whoamI != LSM6DSL_ID ) {
    LOG_ERR("device not found");
    return -1;
  }

  /* Restore default configuration */
  ret |= lsm6dsl_reset_set(&dev_ctx, PROPERTY_ENABLE);

  do {
    ret |= lsm6dsl_reset_get(&dev_ctx, &rst);
  } while (ret == 0 && rst);
//sig motion
  static uint8_t sig_motion_threasold  = 1;
  ret |= lsm6dsl_motion_sens_set(&dev_ctx, 1);  
  ret |= lsm6dsl_motion_threshold_set(&dev_ctx, &sig_motion_threasold);
//end sig motion

  ret |= lsm6dsl_fifo_mode_set(&dev_ctx, LSM6DSL_STREAM_MODE);
  ret |= lsm6dsl_xl_power_mode_set(&dev_ctx, LSM6DSL_XL_NORMAL);
  ret |= lsm6dsl_xl_full_scale_set(&dev_ctx, LSM6DSL_2g);
  ret |= lsm6dsl_xl_reference_mode_set(&dev_ctx, PROPERTY_DISABLE);
  ret |= lsm6dsl_fifo_xl_batch_set(&dev_ctx, LSM6DSL_FIFO_XL_NO_DEC);
  ret |= lsm6dsl_fifo_gy_batch_set(&dev_ctx, LSM6DSL_FIFO_GY_DISABLE);  
  ret |= lsm6dsl_fifo_watermark_set(&dev_ctx, FIFO_BUFFER_LENGTH*fifo_pattern);
  //lsm6dsl_fifo_write_trigger_set(&dev_ctx, LSM6DSL_TRG_XL_GY_DRDY);
  ret |= lsm6dsl_den_mode_set(&dev_ctx, LSM6DSL_LEVEL_LETCHED);
  ret |= lsm6dsl_fifo_data_rate_set(&dev_ctx, LSM6DSL_FIFO_12Hz5); //12Hz5
  ret |= lsm6dsl_rounding_mode_set(&dev_ctx, LSM6DSL_ROUND_XL);
  ret |= lsm6dsl_xl_data_rate_set(&dev_ctx, LSM6DSL_XL_ODR_52Hz);  //52Hz
  ret |= lsm6dsl_xl_hp_bandwidth_set(&dev_ctx, LSM6DSL_XL_HP_ODR_DIV_4);    //DIV_4
  ret |= lsm6dsl_set_interrupts(false);
//  lsm6dsl_tilt_sens_set(&dev_ctx, 1); 
  
  LOG_INF("settigs completed");
  return ret;
}

static uint8_t ble_acc_last_value_buff[4];
static ssize_t read_acc_last_value(struct bt_conn *conn, const struct bt_gatt_attr *attr,
			void *buf, uint16_t len, uint16_t offset)
{
	const uint8_t *value = attr->user_data;	

	return bt_gatt_attr_read(conn, attr, buf, len, offset, value, sizeof(ble_acc_last_value_buff));
}

static struct bt_uuid_128 ble_motion_sensor_result_prop = BT_UUID_INIT_128(
	BT_UUID_128_ENCODE(0x7c3beebb, 0xba2d, 0x4634, 0xa999, 0xf61b91c75f49));

static uint8_t notify_ble_motion_activity_value_on = 0;

static void ble_motion_activity_notify_changed(const struct bt_gatt_attr *attr, uint16_t value) {
	notify_ble_motion_activity_value_on = (value == BT_GATT_CCC_NOTIFY) ? 1 : 0;
}



/* Current Time Service Declaration */
BT_GATT_SERVICE_DEFINE(ble_motion_service,
	BT_GATT_PRIMARY_SERVICE(BT_UUID_DECLARE_16(0x170B)),
	BT_GATT_CHARACTERISTIC(&ble_motion_sensor_result_prop.uuid, 
            BT_GATT_CHRC_READ | BT_GATT_CHRC_NOTIFY,
			      BT_GATT_PERM_READ,
			      read_acc_last_value, NULL, ble_acc_last_value_buff),
	BT_GATT_CCC(ble_motion_activity_notify_changed, BT_GATT_PERM_READ | BT_GATT_PERM_WRITE),
);

static int32_t tilt_has_triggered(const stmdev_ctx_t *ctx, lsm6dsl_func_src1_t *val) {
  uint32_t ret = 0;
  lsm6dsl_func_src1_t result_trig;
  //uint8_t result;
  ret |= lsm6dsl_read_reg(ctx, LSM6DSL_FUNC_SRC1, (uint8_t *)&result_trig, 1);
  *val = result_trig;
  return ret;
}

void ble_showmotion(struct k_work *work)
{
  if(notify_ble_motion_activity_value_on) 
      bt_gatt_notify(NULL, &ble_motion_service.attrs[1], ble_acc_last_value_buff, sizeof(ble_acc_last_value_buff));	
}

K_WORK_DEFINE(work_ble_showmotion, ble_showmotion);

static int fifo_threashold_handler(void) {
  int ret = 0;
  uint16_t num = 0;
  uint32_t counter = 0;
  
  struct xlData average_xl = {0};
  
  ret |= lsm6dsl_fifo_data_level_get(&dev_ctx, &num);  
  LOG_INF("numvalues %d", (int)num);  
  if(num < 1920) {
    //wait for next interrupt to occur
    LOG_INF("buffer not filled");
    return 0;
  }
  
  if(sigMotionDetected) {
    sigMotionDetected = false;
  } else {
    lsm6dsl_config_doubletap(false);
  }

  memset(data_raw_acceleration.u8bit, 0x00, 3*sizeof(int16_t));

  for(int x = 0; x <= (num-fifo_pattern); x+=fifo_pattern) {        
      
    lsm6dsl_fifo_raw_data_get(&dev_ctx, data_raw_acceleration.u8bit, fifo_pattern * sizeof(int16_t));                                                          

    average_xl.x += lsm6dsl_from_fs2g_to_mg(data_raw_acceleration.i16bit[0]);
    average_xl.y += lsm6dsl_from_fs2g_to_mg(data_raw_acceleration.i16bit[1]);
    average_xl.z += lsm6dsl_from_fs2g_to_mg(data_raw_acceleration.i16bit[2]);
    counter++;                        
  }
  average_xl.x/= counter;
  average_xl.y/= counter;
  average_xl.z/= counter;
  LOG_INF("average: %4.2f\t%4.2f\t%4.2f", (double) average_xl.x, (double)average_xl.y, (double)average_xl.z);

  float vector = sqrt(pow(average_xl.x,2)+pow(average_xl.y,2)+pow(average_xl.z,2));
  LOG_INF("average) = %4.2f", (double)vector);
  
  store_tracked(vector);
  memcpy(&ble_acc_last_value_buff, &vector, sizeof(float));
  k_work_submit(&work_ble_showmotion);
  return ret;
}

static void lsm6dsl_data_handler(struct k_work *work)
{  
  lsm6dsl_func_src1_t trigger_received = {0};
  int32_t ret = tilt_has_triggered(&dev_ctx, &trigger_received);
  if(ret) {
    LOG_ERR("unable to read trigger source");
    return;
  }
  // if(trigger_received.tilt_ia) {
  //   LOG_INF("TILT.IA trigger received");   
  //   blink(0);
  // }
  if(trigger_received.sign_motion_ia) {
    LOG_INF("sign_motion_ia trigger received");
    lsm6dsl_config_doubletap(true);
    sigMotionDetected = true;
    blink(1);
  }
  lsm6dsl_tap_src_t tab_detection = {0};
  ret |= lsm6dsl_tap_src_get(&dev_ctx, &tab_detection);
  if(tab_detection.tap_ia) {
    LOG_INF("doubletab detected");
    blink(2);
  }

  if(fifo_threashold_handler()) {
      LOG_ERR("error handling fifo");
  }      
  //gpio_pin_interrupt_configure_dt(&signal, GPIO_INT_LEVEL_HIGH);
}

/*
 * @brief  Write generic device register (platform dependent)
 *
 * @param  handle    customizable argument. In this examples is used in
 *                   order to select the correct sensor bus handler.
 * @param  reg       register to write
 * @param  bufp      pointer to data to write in register reg
 * @param  len       number of consecutive register to write
 *
 */
static int32_t platform_write(void *handle, uint8_t reg, const uint8_t *bufp,
                              uint16_t len)
{  

	int error = i2c_burst_write(i2c, LSM6DSL_ADDR, reg, bufp, len);
  if (error) {
    return -EIO;
  } else {
    return 0;
  };
}

/*
 * @brief  Read generic device register (platform dependent)
 *
 * @param  handle    customizable argument. In this examples is used in
 *                   order to select the correct sensor bus handler.
 * @param  reg       register to read
 * @param  bufp      pointer to buffer that store the data read
 * @param  len       number of consecutive register to read
 *
 */
static int32_t platform_read(void *handle, uint8_t reg, uint8_t *bufp,
                             uint16_t len)
{  
	 if(i2c_burst_read(i2c, LSM6DSL_ADDR, reg, bufp, len)){    
    return -EIO;
   }   
   return 0;
}

/*
 * @brief  platform specific delay (platform dependent)
 *
 * @param  ms        delay in ms
 *
 */
static void platform_delay(uint32_t ms)
{
    k_sleep(K_MSEC(ms));
}

/*
 * @brief  platform specific initialization (platform dependent)
 */
static void platform_init(void)
{
	i2c = DEVICE_DT_GET(DT_NODELABEL(i2c0));
}

SYS_INIT(lsm6dsl_init, APPLICATION, CONFIG_APPLICATION_INIT_PRIORITY);
```

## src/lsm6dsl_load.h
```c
#ifndef LSM6DSL_LOAD_H
#define LSM6DSL_LOAD_H

#define TX_BUF_DIM          1000
#define BOOT_TIME        30 //ms 15ms minimum 
#define LSM6DSL_ADDR 0x6a
#define ZEPHYR_USER_NODE DT_PATH(zephyr_user)
#define fifo_pattern 3 //3x 16 bit for only the accelometer
#define FIFO_BUFFER_LENGTH 675 //=3 byte per sample 12hz5 54sec
// int lsm6dsl_init(struct storage_module *storage);

#endif
```
